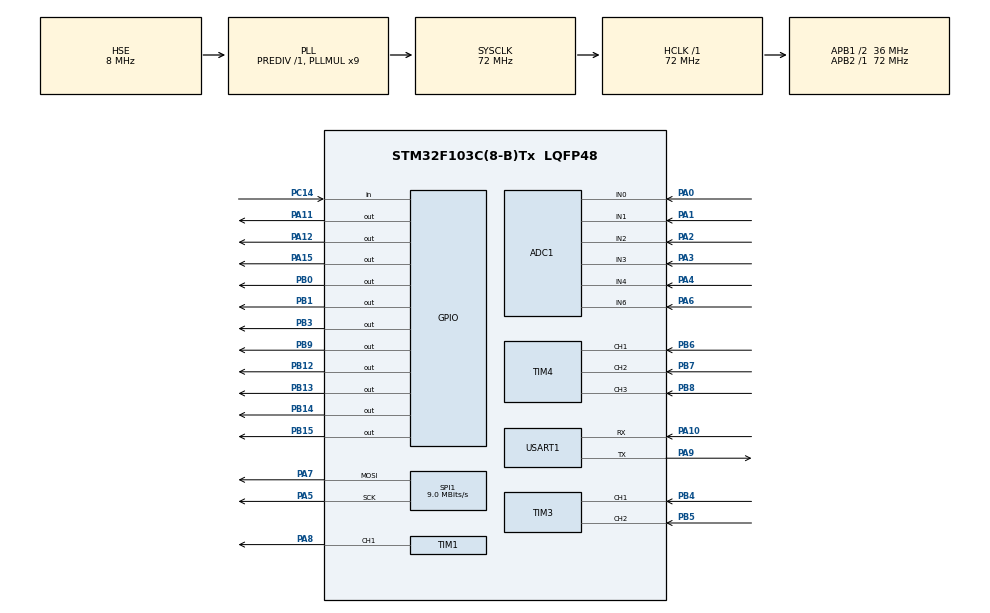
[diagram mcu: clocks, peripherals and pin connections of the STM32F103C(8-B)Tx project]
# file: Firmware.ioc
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ADC1.Channel-0\#ChannelRegularConversion=ADC_CHANNEL_1
ADC1.NbrOfConversionFlag=1
ADC1.Rank-0\#ChannelRegularConversion=1
ADC1.SamplingTime-0\#ChannelRegularConversion=ADC_SAMPLETIME_1CYCLE_5
ADC1.master=1
Mcu.Family=STM32F1
Mcu.Name=STM32F103C(8-B)Tx
Mcu.Package=LQFP48
NVIC.PriorityGroup=NVIC_PRIORITYGROUP_4
PA0-WKUP.Signal=ADCx_IN0
PA1.Signal=ADCx_IN1
PA10.Mode=Asynchronous
PA10.Signal=USART1_RX
PA11.PinState=GPIO_PIN_SET
PA11.Signal=GPIO_Output
PA12.Signal=GPIO_Output
PA13.Mode=Serial_Wire
PA13.Signal=SYS_JTMS-SWDIO
PA14.Mode=Serial_Wire
PA14.Signal=SYS_JTCK-SWCLK
PA15.Signal=GPIO_Output
PA2.Signal=ADCx_IN2
PA3.Signal=ADCx_IN3
PA4.Signal=ADCx_IN4
PA5.Mode=TX_Only_Simplex_Unidirect_Master
PA5.Signal=SPI1_SCK
PA6.Signal=ADCx_IN6
PA7.Mode=TX_Only_Simplex_Unidirect_Master
PA7.Signal=SPI1_MOSI
PA8.Signal=S_TIM1_CH1
PA9.Mode=Asynchronous
PA9.Signal=USART1_TX
PB0.Signal=GPIO_Output
PB1.Signal=GPIO_Output
PB12.Signal=GPIO_Output
PB13.Signal=GPIO_Output
PB14.Signal=GPIO_Output
PB15.Signal=GPIO_Output
PB3.Signal=GPIO_Output
PB4.Signal=S_TIM3_CH1
PB5.Signal=S_TIM3_CH2
PB6.Signal=S_TIM4_CH1
PB7.Signal=S_TIM4_CH2
PB8.Signal=S_TIM4_CH3
PB9.Signal=GPIO_Output
PC14-OSC32_IN.GPIO_PuPd=GPIO_PULLUP
PC14-OSC32_IN.Signal=GPIO_Input
PD0-OSC_IN.Mode=HSE-External-Oscillator
PD0-OSC_IN.Signal=RCC_OSC_IN
PD1-OSC_OUT.Mode=HSE-External-Oscillator
PD1-OSC_OUT.Signal=RCC_OSC_OUT
ProjectManager.HeapSize=0x200
ProjectManager.StackSize=0x400
ProjectManager.TargetToolchain=STM32CubeIDE
RCC.ADCPresc=RCC_ADCPCLK2_DIV6
RCC.AHBFreq_Value=72000000
RCC.APB1CLKDivider=RCC_HCLK_DIV2
RCC.APB1Freq_Value=36000000
RCC.APB1TimFreq_Value=72000000
RCC.APB2Freq_Value=72000000
RCC.APB2TimFreq_Value=72000000
RCC.HCLKFreq_Value=72000000
RCC.PLLMUL=RCC_PLL_MUL9
RCC.PLLSourceVirtual=RCC_PLLSOURCE_HSE
RCC.SYSCLKFreq_VALUE=72000000
RCC.SYSCLKSource=RCC_SYSCLKSOURCE_PLLCLK
RCC.USBFreq_Value=72000000
SH.ADCx_IN0.0=ADC1_IN0,IN0
SH.ADCx_IN1.0=ADC1_IN1,IN1
SH.ADCx_IN2.0=ADC1_IN2,IN2
SH.ADCx_IN3.0=ADC1_IN3,IN3
SH.ADCx_IN4.0=ADC1_IN4,IN4
SH.ADCx_IN6.0=ADC1_IN6,IN6
SH.S_TIM1_CH1.0=TIM1_CH1,PWM Generation1 CH1
SH.S_TIM3_CH1.0=TIM3_CH1,Encoder_Interface
SH.S_TIM3_CH2.0=TIM3_CH2,Encoder_Interface
SH.S_TIM4_CH1.0=TIM4_CH1,Input_Capture1_from_TI1
SH.S_TIM4_CH2.0=TIM4_CH2,Input_Capture2_from_TI2
SH.S_TIM4_CH3.0=TIM4_CH3,Input_Capture3_from_TI3
SPI1.BaudRatePrescaler=SPI_BAUDRATEPRESCALER_8
SPI1.CalculateBaudRate=9.0 MBits/s
SPI1.Direction=SPI_DIRECTION_2LINES
SPI1.Mode=SPI_MODE_MASTER
SPI1.VirtualType=VM_MASTER
TIM1.Channel-PWM\ Generation1\ CH1=TIM_CHANNEL_1
TIM4.Channel-Input_Capture1_from_TI1=TIM_CHANNEL_1
TIM4.Channel-Input_Capture2_from_TI2=TIM_CHANNEL_2
TIM4.Channel-Input_Capture3_from_TI3=TIM_CHANNEL_3
USART1.VirtualMode=VM_ASYNC
VP_TIM1_VS_ClockSourceINT.Mode=Internal
VP_TIM4_VS_ClockSourceINT.Mode=Internal
board=custom

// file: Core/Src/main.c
/* USER CODE BEGIN Header */
/**
  ******************************************************************************
  * @file           : main.c
  * @brief          : Main program body
  ******************************************************************************
  * @attention
  *
  * Copyright (c) 2026 STMicroelectronics.
  * All rights reserved.
  *
  * This software is licensed under terms that can be found in the LICENSE file
  * in the root directory of this software component.
  * If no LICENSE file comes with this software, it is provided AS-IS.
  *
  ******************************************************************************
  */
/* USER CODE END Header */
#include "main.h"
#include "adc.h"
#include "spi.h"
#include "tim.h"
#include "usart.h"
#include "gpio.h"

/* USER CODE BEGIN Includes */
#include "st7735.h"
#include "fonts.h"
/* USER CODE END Includes */

void SystemClock_Config(void);

int main(void)
{

  /* MCU Configuration--------------------------------------------------------*/

  /* Reset of all peripherals, Initializes the Flash interface and the Systick. */
  HAL_Init();

  /* Configure the system clock */
  SystemClock_Config();

  /* Initialize all configured peripherals */
  MX_GPIO_Init();
  MX_ADC1_Init();
  MX_SPI1_Init();
  MX_TIM1_Init();
  MX_TIM3_Init();
  MX_TIM4_Init();
  MX_USART1_UART_Init();
  /* USER CODE BEGIN 2 */
  /* USER CODE BEGIN 2 */

    // 1. Утримуємо живлення приладу увімкненим (пін PB9 -> High)
    // Якщо цього не зробити, тестер вимкнеться відразу після відпускання кнопки
    HAL_GPIO_WritePin(GPIOB, GPIO_PIN_9, GPIO_PIN_SET);

    // 2. Гарантовано вимикаємо захисне реле (PB3 -> Low)
    HAL_GPIO_WritePin(GPIOB, GPIO_PIN_3, GPIO_PIN_RESET);

    // 3. Обов'язкове апаратне калібрування АЦП перед вимірюваннями
    HAL_ADCEx_Calibration_Start(&hadc1);

    // 4. Запускаємо таймер енкодера (щоб він почав рахувати оберти)
    HAL_TIM_Encoder_Start(&htim3, TIM_CHANNEL_ALL);
    ST7735_Init();
    ST7735_FillScreen(ST7735_BLACK);
    ST7735_WriteString(10, 10, "Tester OK", Font_11x18, ST7735_GREEN, ST7735_BLACK);

    // Ініціалізація екрана (виберіть правильний тип, зазвичай це INITR_BLACKTAB або INITR_GREENTAB)
    ST7735_Init();

    // Заливаємо екран чорним кольором
    ST7735_FillScreen(ST7735_BLACK);

    // Пишемо текст: координата X, координата Y, текст, шрифт, колір тексту, колір фону
    ST7735_WriteString(10, 10, "Tester Init...", Font_11x18, ST7735_GREEN, ST7735_BLACK);
    ST7735_WriteString(10, 35, "V 1.0", Font_7x10, ST7735_WHITE, ST7735_BLACK);
    /* USER CODE END 2 */
  /* USER CODE END 2 */

  /* Infinite loop */
  while (1)
  {

  }
}

void SystemClock_Config(void)
{
  RCC_OscInitTypeDef RCC_OscInitStruct = {0};
  RCC_ClkInitTypeDef RCC_ClkInitStruct = {0};
  RCC_PeriphCLKInitTypeDef PeriphClkInit = {0};

  /** Initializes the RCC Oscillators according to the specified parameters
  * in the RCC_OscInitTypeDef structure.
  */
  RCC_OscInitStruct.OscillatorType = RCC_OSCILLATORTYPE_HSE;
  RCC_OscInitStruct.HSEState = RCC_HSE_ON;
  RCC_OscInitStruct.HSEPredivValue = RCC_HSE_PREDIV_DIV1;
  RCC_OscInitStruct.HSIState = RCC_HSI_ON;
  RCC_OscInitStruct.PLL.PLLState = RCC_PLL_ON;
  RCC_OscInitStruct.PLL.PLLSource = RCC_PLLSOURCE_HSE;
  RCC_OscInitStruct.PLL.PLLMUL = RCC_PLL_MUL9;
  if (HAL_RCC_OscConfig(&RCC_OscInitStruct) != HAL_OK)
  {
    Error_Handler();
  }

  /** Initializes the CPU, AHB and APB buses clocks
  */
  RCC_ClkInitStruct.ClockType = RCC_CLOCKTYPE_HCLK|RCC_CLOCKTYPE_SYSCLK
                              |RCC_CLOCKTYPE_PCLK1|RCC_CLOCKTYPE_PCLK2;
  RCC_ClkInitStruct.SYSCLKSource = RCC_SYSCLKSOURCE_PLLCLK;
  RCC_ClkInitStruct.AHBCLKDivider = RCC_SYSCLK_DIV1;
  RCC_ClkInitStruct.APB1CLKDivider = RCC_HCLK_DIV2;
  RCC_ClkInitStruct.APB2CLKDivider = RCC_HCLK_DIV1;

  if (HAL_RCC_ClockConfig(&RCC_ClkInitStruct, FLASH_LATENCY_2) != HAL_OK)
  {
    Error_Handler();
  }
  PeriphClkInit.PeriphClockSelection = RCC_PERIPHCLK_ADC;
  PeriphClkInit.AdcClockSelection = RCC_ADCPCLK2_DIV6;
  if (HAL_RCCEx_PeriphCLKConfig(&PeriphClkInit) != HAL_OK)
  {
    Error_Handler();
  }
}

void Error_Handler(void)
{
  __disable_irq();
  while (1)
  {
  }
}
